# M4KP register map
File version: 0.1
Registers are 32-bit, read-write, reset 0x0 unless marked. A register's access mark holds for its fields unless they carry their own. Offsets are from the block's base; [hi:lo] are bit positions; {n}, {i} and the like mark numbered series.

## PK — Port K
Base 0x400E0900
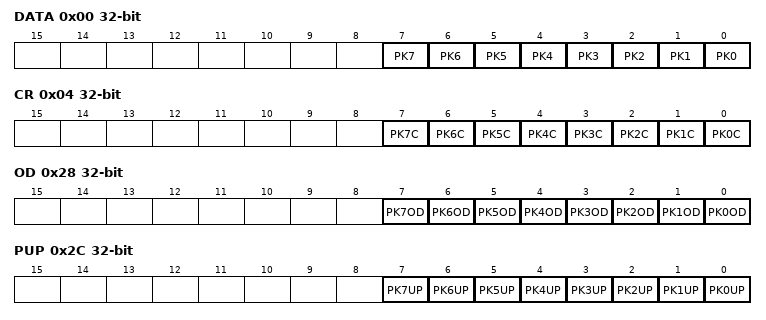
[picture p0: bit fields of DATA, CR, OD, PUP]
0x00 DATA — Port K Data Register
  [n] PK{n} (n=0..7)
0x04 CR — Port K Output Control Register
  [n] PK{n}C (n=0..7)
0x28 OD — Port K Open Drain Control Register
  [n] PK{n}OD (n=0..7)
0x2C PUP — Port K Pull-up Control Register
  [n] PK{n}UP (n=0..7)
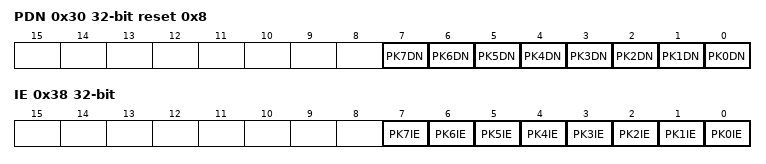
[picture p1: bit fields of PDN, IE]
0x30 PDN reset 0x8 — Port K Pull-down Control Register
  [n] PK{n}DN (n=0..7)
0x38 IE — Port K Input Control Register
  [n] PK{n}IE (n=0..7)

## PL — Port L
Base 0x400E0A00
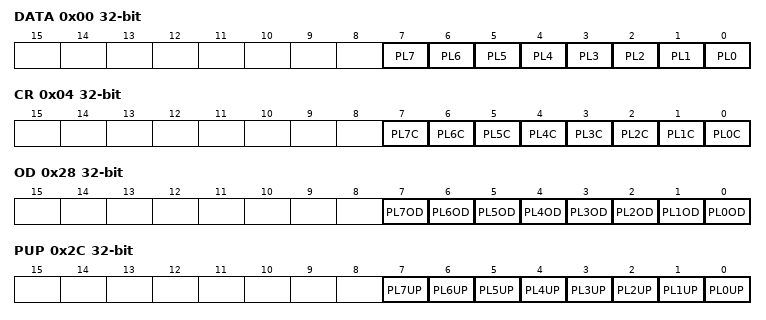
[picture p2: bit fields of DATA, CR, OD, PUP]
0x00 DATA — Port L Data Register
  [n] PL{n} (n=0..7)
0x04 CR — Port L Output Control Register
  [n] PL{n}C (n=0..7)
0x28 OD — Port L Open Drain Control Register
  [n] PL{n}OD (n=0..7)
0x2C PUP — Port L Pull-up Control Register
  [n] PL{n}UP (n=0..7)
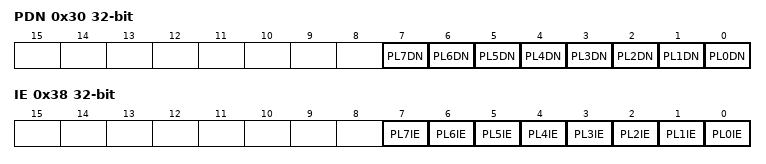
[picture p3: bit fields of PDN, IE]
0x30 PDN — Port L Pull-down Control Register
  [n] PL{n}DN (n=0..7)
0x38 IE — Port L Input Control Register
  [n] PL{n}IE (n=0..7)

## PM — Port M
Base 0x400E0B00
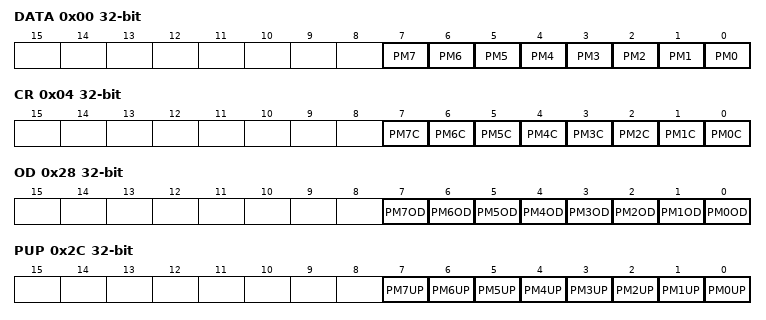
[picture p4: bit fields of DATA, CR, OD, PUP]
0x00 DATA — Port M Data Register
  [n] PM{n} (n=0..7)
0x04 CR — Port M Output Control Register
  [n] PM{n}C (n=0..7)
0x28 OD — Port M Open Drain Control Register
  [n] PM{n}OD (n=0..7)
0x2C PUP — Port M Pull-up Control Register
  [n] PM{n}UP (n=0..7)
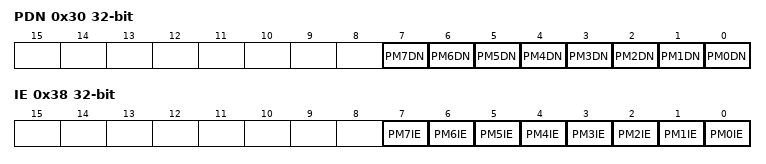
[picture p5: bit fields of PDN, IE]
0x30 PDN — Port M Pull-down Control Register
  [n] PM{n}DN (n=0..7)
0x38 IE — Port M Input Control Register
  [n] PM{n}IE (n=0..7)

## PN — Port N
Base 0x400E0C00
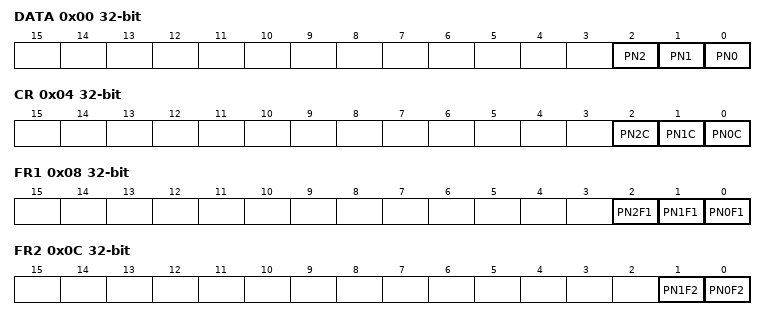
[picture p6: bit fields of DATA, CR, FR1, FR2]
0x00 DATA — Port N Data Register
  [2] PN2, [1] PN1, [0] PN0
0x04 CR — Port N Output Control Register
  [2] PN2C, [1] PN1C, [0] PN0C
0x08 FR1 — Port N Function Register 1
  [2] PN2F1, [1] PN1F1, [0] PN0F1
0x0C FR2 — Port N Function Register 2
  [1] PN1F2, [0] PN0F2
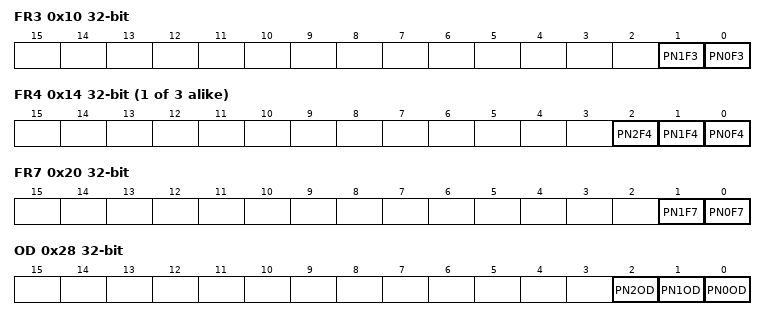
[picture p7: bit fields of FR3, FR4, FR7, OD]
0x10 FR3 — Port N Function Register 3
  [1] PN1F3, [0] PN0F3
{0x4+4i} FR{i} (i=4..6) — Port N Function Register {i}
  [2] PN2F{i}, [1] PN1F{i}, [0] PN0F{i}
0x20 FR7 — Port N Function Register 7
  [1] PN1F7, [0] PN0F7
0x28 OD — Port N Opend Drain Control Register
  [2] PN2OD, [1] PN1OD, [0] PN0OD
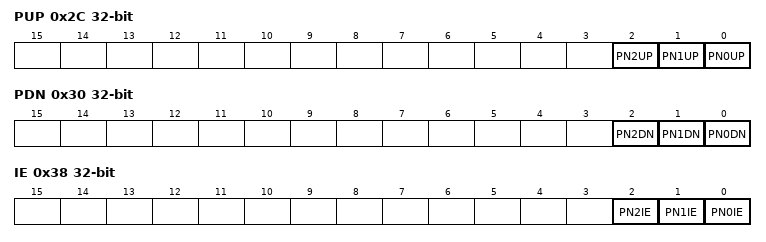
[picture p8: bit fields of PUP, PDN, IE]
0x2C PUP — Port N Pull-up Control Register
  [2] PN2UP, [1] PN1UP, [0] PN0UP
0x30 PDN — Port N Pull-down Control Register
  [2] PN2DN, [1] PN1DN, [0] PN0DN
0x38 IE — Port N Input Control Register
  [2] PN2IE, [1] PN1IE, [0] PN0IE

## PP — Port P
Base 0x400E0D00
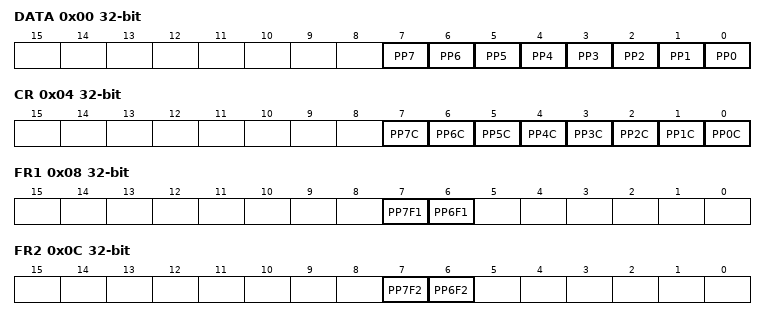
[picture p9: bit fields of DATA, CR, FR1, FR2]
0x00 DATA — Port P Data Register
  [n] PP{n} (n=0..7)
0x04 CR — Port P Output Control Register
  [n] PP{n}C (n=0..7)
0x08 FR1 — Port P Function Register 1
  [7] PP7F1, [6] PP6F1
0x0C FR2 — Port P Function Register 2
  [7] PP7F2, [6] PP6F2
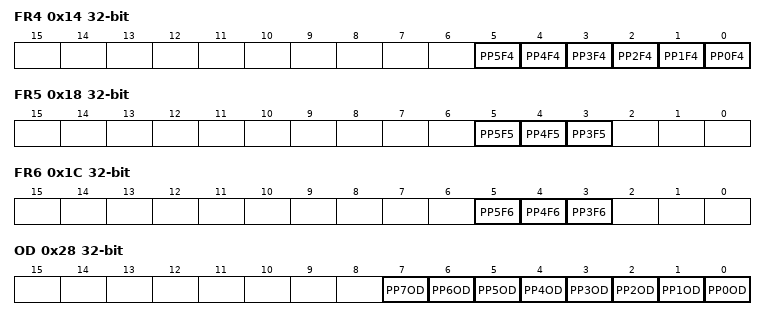
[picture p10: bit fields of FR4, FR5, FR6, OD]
0x14 FR4 — Port P Function Register 4
  [n] PP{n}F4 (n=0..5)
0x18 FR5 — Port P Function Register 5
  [5] PP5F5, [4] PP4F5, [3] PP3F5
0x1C FR6 — Port P Function Register 6
  [5] PP5F6, [4] PP4F6, [3] PP3F6
0x28 OD — Port P Open Drain Control Register
  [n] PP{n}OD (n=0..7)
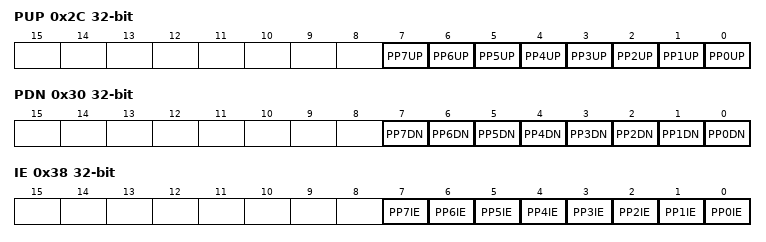
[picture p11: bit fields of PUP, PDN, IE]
0x2C PUP — Port P Pull-up Control Register
  [n] PP{n}UP (n=0..7)
0x30 PDN — Port P Pull-down Control Register
  [n] PP{n}DN (n=0..7)
0x38 IE — Port P Input Control Register
  [n] PP{n}IE (n=0..7)

## PT — Port T
Base 0x400E0F00
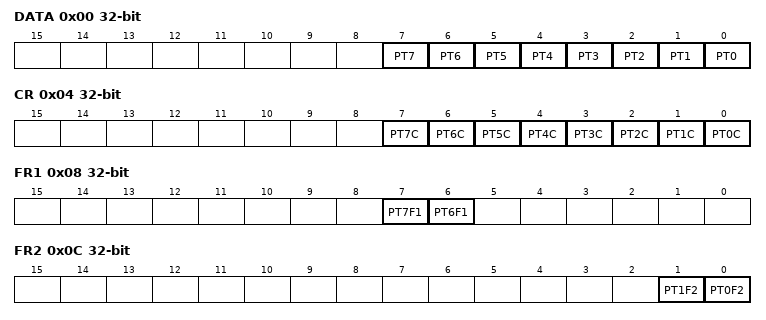
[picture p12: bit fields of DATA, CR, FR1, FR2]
0x00 DATA — Port T Data Register
  [n] PT{n} (n=0..7)
0x04 CR — Port T Output Control Register
  [n] PT{n}C (n=0..7)
0x08 FR1 — Port T Function Register 1
  [7] PT7F1, [6] PT6F1
0x0C FR2 — Port T Function Register 2
  [1] PT1F2, [0] PT0F2
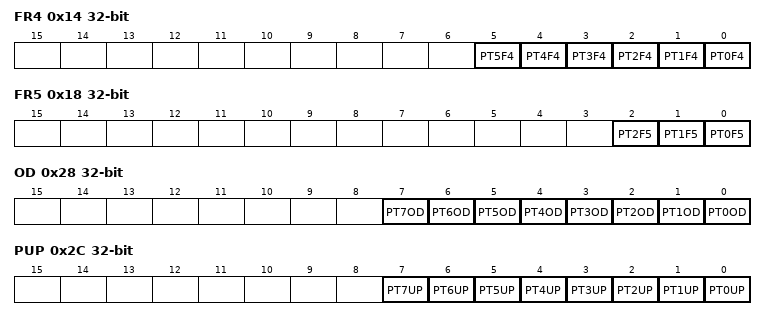
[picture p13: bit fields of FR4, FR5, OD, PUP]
0x14 FR4 — Port T Function Register 4
  [n] PT{n}F4 (n=0..5)
0x18 FR5 — Port T Function Register 5
  [2] PT2F5, [1] PT1F5, [0] PT0F5
0x28 OD — Port T Open Drain Control Register
  [n] PT{n}OD (n=0..7)
0x2C PUP — Port T Pull-up Control Register
  [n] PT{n}UP (n=0..7)
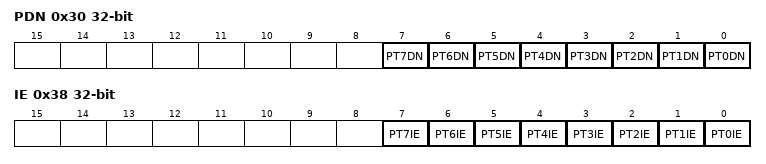
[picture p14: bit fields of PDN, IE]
0x30 PDN — Port T Pull-down Control Register
  [n] PT{n}DN (n=0..7)
0x38 IE — Port T Input Control Register
  [n] PT{n}IE (n=0..7)

## PU — Port U
Base 0x400E1000
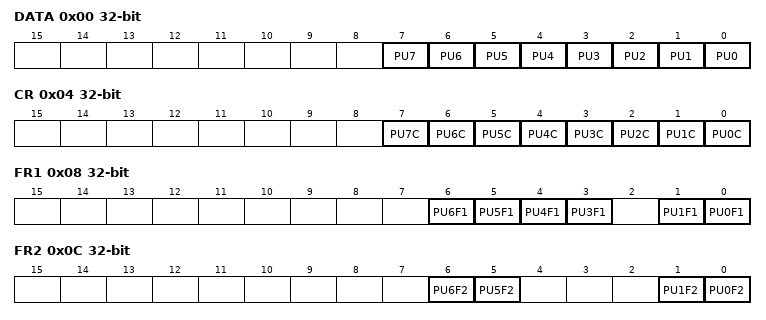
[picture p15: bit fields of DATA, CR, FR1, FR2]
0x00 DATA — Port U Data Register
  [n] PU{n} (n=0..7)
0x04 CR — Port U Output Control Register
  [n] PU{n}C (n=0..7)
0x08 FR1 — Port U Function Register 1
  [n] PU{n}F1 (n=3..6), [1] PU1F1, [0] PU0F1
0x0C FR2 — Port U Function Register 2
  [6] PU6F2, [5] PU5F2, [1] PU1F2, [0] PU0F2
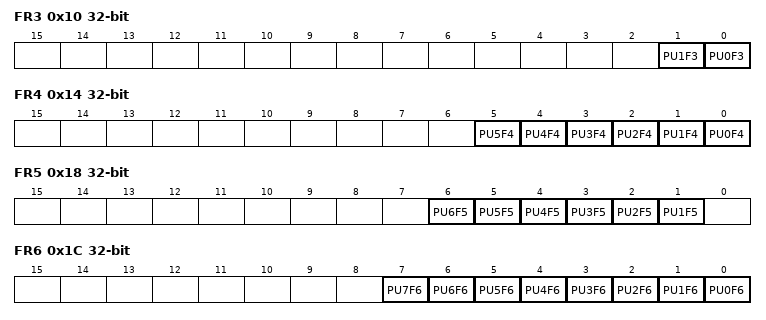
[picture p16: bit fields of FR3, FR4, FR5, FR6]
0x10 FR3 — Port U Function Register 3
  [1] PU1F3, [0] PU0F3
0x14 FR4 — Port U Function Register 4
  [n] PU{n}F4 (n=0..5)
0x18 FR5 — Port U Function Register 5
  [n] PU{n}F5 (n=1..6)
0x1C FR6 — Port U Function Register 6
  [n] PU{n}F6 (n=0..7)
0x20 FR7 — Port U Function Register 7
  [7] PU7F7
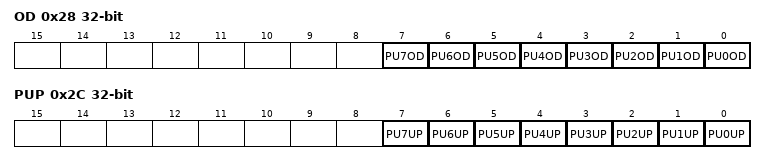
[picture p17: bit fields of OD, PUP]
0x28 OD — Port U Open Drain Control Register
  [n] PU{n}OD (n=0..7)
0x2C PUP — Port U Pull-up Control Register
  [n] PU{n}UP (n=0..7)
0x30 PDN — Port U Pull-down Control Register
  [n] PU{n}DN (n=0..7)
0x38 IE — Port U Input Control Register
  [n] PU{n}IE (n=0..7)
